AUTOSAR XML (schema 314)
package /ComponentType
  internal behavior Sa_ShtdnMech_InternalBehavior: component=Sa_ShtdnMech
    timing event TMT_ShtdnMech_Per1: start-on-event=ShtdnMech_Per1, period=0.01
    port-api-options:
      enable-take-address=false, indirect-api=false, port=FetDrvReset
      enable-take-address=false, indirect-api=false, port=SysFault2
      enable-take-address=false, indirect-api=false, port=SysFault3
    runnable ShtdnMech_Per1
      sync call SC_FetDrvReset_OP_GET: operation=FetDrvReset.OP_GET, timeout=0
      sync call SC_SysFault2_OP_GET: operation=SysFault2.OP_GET, timeout=0
      sync call SC_SysFault3_OP_GET: operation=SysFault3.OP_GET, timeout=0
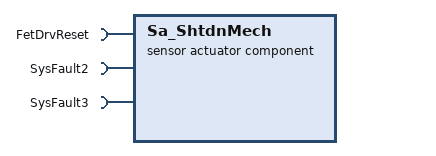
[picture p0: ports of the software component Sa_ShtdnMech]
  sensor actuator software component type Sa_ShtdnMech
    require port FetDrvReset: required-com-specs=[OP_GET, OP_SET], required-interface=FetDrvReset
    require port SysFault2: required-com-specs=[OP_GET, OP_SET], required-interface=SysFault2
    require port SysFault3: required-com-specs=[OP_GET, OP_SET], required-interface=SysFault3
  swc implementation Sa_ShtdnMech_Implementation: behavior=Sa_ShtdnMech_InternalBehavior
    code-descriptors:
      code Code: type=SRC
